# SAM3SD8C register map
File version: 0
Atmel SAM3SD8C Microcontroller
Registers are 32-bit, read-write, reset 0x0 unless marked. A register's access mark holds for its fields unless they carry their own. Offsets are from the block's base; lines under a group give offsets from that group; [hi:lo] are bit positions; {n}, {i} and the like mark numbered series; 'fields as' and 'values as' point back to an identical list; <NAME> marks a mode.

## Memory map
0x40000000 HSMCI size 0x4000 — High Speed MultiMedia Card Interface
0x40004000 SSC size 0x4000 — Synchronous Serial Controller
0x40008000 SPI size 0x4000 — Serial Peripheral Interface
0x40010000 TC0 size 0x4000 — Timer Counter 0
0x40014000 TC1 size 0x4000 — Timer Counter 1
0x40018000 TWI0 size 0x4000 — Two-wire Interface 0
0x4001C000 TWI1 size 0x4000 — Two-wire Interface 1
0x40020000 PWM size 0x4000 — Pulse Width Modulation Controller
0x40024000 USART0 size 0x4000 — Universal Synchronous Asynchronous Receiver Transmitter 0
0x40028000 USART1 size 0x4000 — Universal Synchronous Asynchronous Receiver Transmitter 1
0x4002C000 USART2 size 0x4000 — Universal Synchronous Asynchronous Receiver Transmitter 2
0x40034000 UDP size 0x4000 — USB Device Port
0x40038000 ADC size 0x4000 — Analog-to-digital Converter
0x4003C000 DACC size 0x4000 — Digital-to-Analog Converter Controller
0x40040000 ACC size 0x4000 — Analog Comparator Controller
0x40044000 CRCCU size 0x4000 — Cyclic Redundancy Check Calculation Unit
0x400E0000 SMC size 0x200 — Static Memory Controller
0x400E0200 MATRIX size 0x200 — AHB Bus Matrix
0x400E0400 PMC size 0x140 — Power Management Controller
0x400E0600 UART0 size 0x128 — Universal Asynchronous Receiver Transmitter 0
0x400E0740 CHIPID size 0x200 — Chip Identifier
0x400E0800 UART1 size 0x128 — Universal Asynchronous Receiver Transmitter 1
0x400E0A00 EFC size 0x200 — Embedded Flash Controller
0x400E0E00 PIOA size 0x200 — Parallel Input/Output Controller A
0x400E1000 PIOB size 0x200 — Parallel Input/Output Controller B
0x400E1200 PIOC size 0x200 — Parallel Input/Output Controller C
0x400E1400 RSTC size 0x200 — Reset Controller
0x400E1410 SUPC size 0x200 — Supply Controller
0x400E1430 RTT size 0x200 — Real-time Timer
0x400E1450 WDT size 0x200 — Watchdog Timer
0x400E1460 RTC size 0x200 — Real-time Clock
0x400E1490 GPBR size 0x200 — General Purpose Backup Register

## Interrupts
5 ID_PMC (PMC)
6 ID_EFC (EFC)
8 ID_UART0 (UART0)
9 ID_UART1 (UART1)
11 ID_PIOA (PIOA)
12 ID_PIOB (PIOB)
13 ID_PIOC (PIOC)
14 ID_USART0 (USART0)
15 ID_USART1 (USART1)
16 ID_USART2 (USART2)
18 ID_HSMCI (HSMCI)
19 ID_TWI0 (TWI0)
20 ID_TWI1 (TWI1)
21 ID_SPI (SPI)
22 ID_SSC (SSC)
23 ID_TC0 (TC0)
24 ID_TC1 (TC0)
25 ID_TC2 (TC0)
26 ID_TC3 (TC1)
27 ID_TC4 (TC1)
28 ID_TC5 (TC1)
29 ID_ADC (ADC)
30 ID_DACC (DACC)
31 ID_PWM (PWM)
32 ID_CRCCU (CRCCU)
33 ID_ACC (ACC)
34 ID_UDP (UDP)

## UDP — USB Device Port
Base 0x40034000; register names take the prefix UDP_
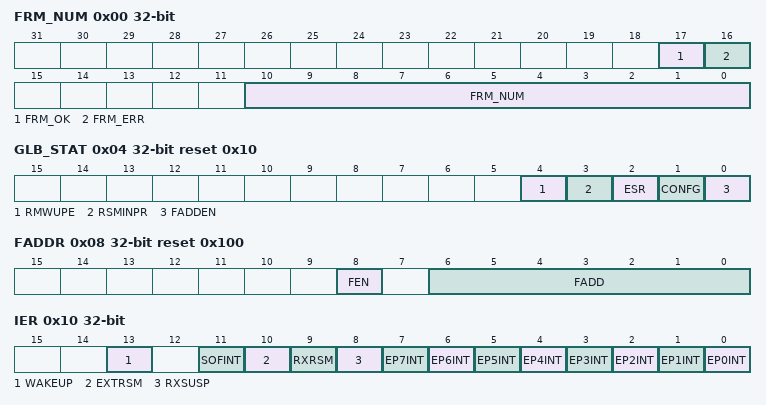
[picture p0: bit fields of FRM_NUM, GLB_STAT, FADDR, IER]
0x00 FRM_NUM ro — Frame Number Register
  [17] FRM_OK — Frame OK
  [16] FRM_ERR — Frame Error
  [10:0] FRM_NUM — Frame Number as Defined in the Packet Field Formats
0x04 GLB_STAT reset 0x10 — Global State Register
  [4] RMWUPE — Remote Wake Up Enable
  [3] RSMINPR
  [2] ESR — Enable Send Resume
  [1] CONFG — Configured
  [0] FADDEN — Function Address Enable
0x08 FADDR reset 0x100 — Function Address Register
  [8] FEN — Function Enable
  [6:0] FADD — Function Address Value
0x10 IER wo reset not defined — Interrupt Enable Register
  [13] WAKEUP — Enable UDP bus Wakeup Interrupt
  [11] SOFINT — Enable Start Of Frame Interrupt
  [10] EXTRSM
  [9] RXRSM — Enable UDP Resume Interrupt
  [8] RXSUSP — Enable UDP Suspend Interrupt
  [n] EP{n}INT (n=3..7) — Enable Endpoint {n} Interrupt
  [2] EP2INT — Enable Endpoint 2Interrupt
  [1] EP1INT — Enable Endpoint 1 Interrupt
  [0] EP0INT — Enable Endpoint 0 Interrupt
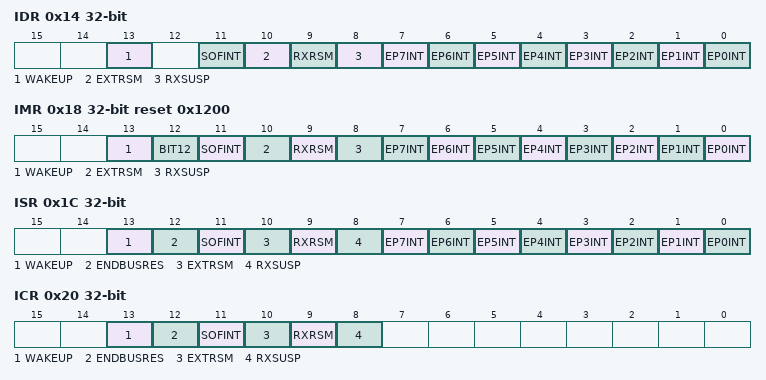
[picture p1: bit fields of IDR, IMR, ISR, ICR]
0x14 IDR wo reset not defined — Interrupt Disable Register
  [13] WAKEUP — Disable USB Bus Interrupt
  [11] SOFINT — Disable Start Of Frame Interrupt
  [10] EXTRSM
  [9] RXRSM — Disable UDP Resume Interrupt
  [8] RXSUSP — Disable UDP Suspend Interrupt
  [n] EP{n}INT (n=0..7) — Disable Endpoint {n} Interrupt
0x18 IMR ro reset 0x1200 — Interrupt Mask Register
  [13] WAKEUP — USB Bus WAKEUP Interrupt
  [12] BIT12 — UDP_IMR Bit 12
  [11] SOFINT — Mask Start Of Frame Interrupt
  [10] EXTRSM
  [9] RXRSM — Mask UDP Resume Interrupt.
  [8] RXSUSP — Mask UDP Suspend Interrupt
  [n] EP{n}INT (n=0..7) — Mask Endpoint {n} Interrupt
0x1C ISR ro reset not defined — Interrupt Status Register
  [13] WAKEUP — UDP Resume Interrupt Status
  [12] ENDBUSRES — End of BUS Reset Interrupt Status
  [11] SOFINT — Start of Frame Interrupt Status
  [10] EXTRSM
  [9] RXRSM — UDP Resume Interrupt Status
  [8] RXSUSP — UDP Suspend Interrupt Status
  [7] EP7INT — Endpoint 7Interrupt Status
  [n] EP{n}INT (n=0..6) — Endpoint {n} Interrupt Status
0x20 ICR wo reset not defined — Interrupt Clear Register
  [13] WAKEUP — Clear Wakeup Interrupt
  [12] ENDBUSRES — Clear End of Bus Reset Interrupt
  [11] SOFINT — Clear Start Of Frame Interrupt
  [10] EXTRSM
  [9] RXRSM — Clear UDP Resume Interrupt
  [8] RXSUSP — Clear UDP Suspend Interrupt
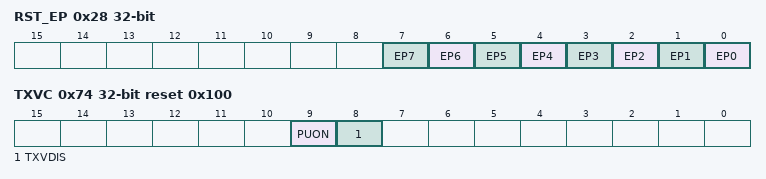
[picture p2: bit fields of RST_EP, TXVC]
0x28 RST_EP — Reset Endpoint Register
  [n] EP{n} (n=0..7) — Reset Endpoint {n}
{0x30+4i} CSR{i} (i=0..7) reset not defined — Endpoint Control and Status Register
  [26:16] RXBYTECNT — Number of Bytes Available in the FIFO
  [15] EPEDS — Endpoint Enable Disable
  [11] DTGLE — Data Toggle
  [10:8] EPTYPE — Endpoint Type
    0=CTRL (Control); 1=ISO_OUT (Isochronous OUT); 2=BULK_OUT; 3=INT_OUT (Interrupt OUT); 5=ISO_IN (Isochronous IN); 6=BULK_IN; 7=INT_IN (Interrupt IN)
  [7] DIR — Transfer Direction (only available for control endpoints)
  [6] RX_DATA_BK1 — Receive Data Bank 1 (only used by endpoints with ping-pong attributes)
  [5] FORCESTALL — Force Stall (used by Control, Bulk and Isochronous Endpoints)
  [4] TXPKTRDY — Transmit Packet Ready
  [3] STALLSENT — Stall Sent (Control, Bulk Interrupt Endpoints)/ISOERROR (Isochronous Endpoints)
  [3] ISOERROR — Stall Sent (Control, Bulk Interrupt Endpoints)/ISOERROR (Isochronous Endpoints)
  [2] RXSETUP — Received Setup
  [1] RX_DATA_BK0 — Receive Data Bank 0
  [0] TXCOMP — Generates an IN Packet with Data Previously Written in the DPR
{0x50+4i} FDR{i} (i=0..7) reset not defined — Endpoint FIFO Data Register
  [7:0] FIFO_DATA — FIFO Data Value
0x74 TXVC reset 0x100 — Transceiver Control Register
  [9] PUON — Pullup On
  [8] TXVDIS — Transceiver Disable

## Notices in the file
Copyright (c) 2011, Atmel Corporation
All rights reserved.
Redistribution and use in source and binary forms, with or without
modification, are permitted provided that the following condition is met:
- Redistributions of source code must retain the above copyright notice,
this list of conditions and the disclaimer below.
Atmel's name may not be used to endorse or promote products derived from
this software without specific prior written permission.
DISCLAIMER:  THIS SOFTWARE IS PROVIDED BY ATMEL "AS IS" AND ANY EXPRESS OR
IMPLIED WARRANTIES, INCLUDING, BUT NOT LIMITED TO, THE IMPLIED WARRANTIES OF
MERCHANTABILITY, FITNESS FOR A PARTICULAR PURPOSE AND NON-INFRINGEMENT ARE
DISCLAIMED. IN NO EVENT SHALL ATMEL BE LIABLE FOR ANY DIRECT, INDIRECT,
INCIDENTAL, SPECIAL, EXEMPLARY, OR CONSEQUENTIAL DAMAGES (INCLUDING, BUT NOT
LIMITED TO, PROCUREMENT OF SUBSTITUTE GOODS OR SERVICES; LOSS OF USE, DATA,
OR PROFITS; OR BUSINESS INTERRUPTION) HOWEVER CAUSED AND ON ANY THEORY OF
LIABILITY, WHETHER IN CONTRACT, STRICT LIABILITY, OR TORT (INCLUDING
NEGLIGENCE OR OTHERWISE) ARISING IN ANY WAY OUT OF THE USE OF THIS SOFTWARE,
EVEN IF ADVISED OF THE POSSIBILITY OF SUCH DAMAGE.
